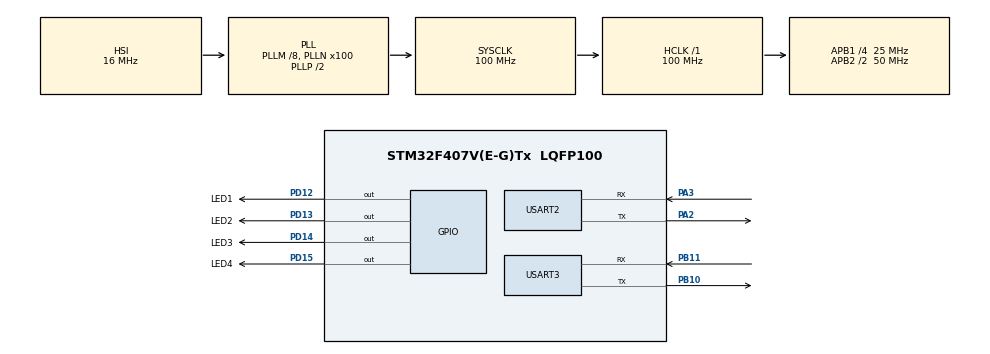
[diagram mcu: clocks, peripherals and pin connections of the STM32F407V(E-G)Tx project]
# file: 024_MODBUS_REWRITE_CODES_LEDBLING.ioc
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Mcu.Family=STM32F4
Mcu.Name=STM32F407V(E-G)Tx
Mcu.Package=LQFP100
NVIC.PriorityGroup=NVIC_PRIORITYGROUP_4
NVIC.TIM1_UP_TIM10_IRQn=true\:0\:0\:false\:false\:true\:true\:true\:true
NVIC.USART2_IRQn=true\:0\:0\:false\:false\:true\:true\:true\:true
PA13.Mode=Serial_Wire
PA13.Signal=SYS_JTMS-SWDIO
PA14.Mode=Serial_Wire
PA14.Signal=SYS_JTCK-SWCLK
PA2.Mode=Asynchronous
PA2.Signal=USART2_TX
PA3.Mode=Asynchronous
PA3.Signal=USART2_RX
PB10.Mode=Asynchronous
PB10.Signal=USART3_TX
PB11.Mode=Asynchronous
PB11.Signal=USART3_RX
PC14-OSC32_IN.Mode=LSE-External-Oscillator
PC14-OSC32_IN.Signal=RCC_OSC32_IN
PC15-OSC32_OUT.Mode=LSE-External-Oscillator
PC15-OSC32_OUT.Signal=RCC_OSC32_OUT
PD12.GPIO_Label=LED1
PD12.Signal=GPIO_Output
PD13.GPIO_Label=LED2
PD13.Signal=GPIO_Output
PD14.GPIO_Label=LED3
PD14.Signal=GPIO_Output
PD15.GPIO_Label=LED4
PD15.Signal=GPIO_Output
PH0-OSC_IN.Mode=HSE-External-Oscillator
PH0-OSC_IN.Signal=RCC_OSC_IN
PH1-OSC_OUT.Mode=HSE-External-Oscillator
PH1-OSC_OUT.Signal=RCC_OSC_OUT
ProjectManager.HeapSize=0x200
ProjectManager.StackSize=0x400
ProjectManager.TargetToolchain=STM32CubeIDE
RCC.48MHZClocksFreq_Value=50000000
RCC.AHBFreq_Value=100000000
RCC.APB1CLKDivider=RCC_HCLK_DIV4
RCC.APB1Freq_Value=25000000
RCC.APB1TimFreq_Value=50000000
RCC.APB2CLKDivider=RCC_HCLK_DIV2
RCC.APB2Freq_Value=50000000
RCC.APB2TimFreq_Value=100000000
RCC.CortexFreq_Value=100000000
RCC.HCLKFreq_Value=100000000
RCC.HSE_VALUE=25000000
RCC.HSI_VALUE=16000000
RCC.PLLM=8
RCC.PLLN=100
RCC.SYSCLKFreq_VALUE=100000000
RCC.SYSCLKSource=RCC_SYSCLKSOURCE_PLLCLK
RCC.VCOOutputFreq_Value=200000000
TIM10.Period=10000
TIM10.Prescaler=10000
USART2.VirtualMode=VM_ASYNC
USART3.VirtualMode=VM_ASYNC
VP_TIM10_VS_ClockSourceINT.Mode=Enable_Timer
VP_TIM1_VS_ClockSourceINT.Mode=Internal
board=custom

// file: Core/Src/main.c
/* USER CODE BEGIN Header */
/**
  ******************************************************************************
  * @file           : main.c
  * @brief          : Main program body
  ******************************************************************************
  * @attention
  *
  * Copyright (c) 2024 STMicroelectronics.
  * All rights reserved.
  *
  * This software is licensed under terms that can be found in the LICENSE file
  * in the root directory of this software component.
  * If no LICENSE file comes with this software, it is provided AS-IS.
  *
  ******************************************************************************
  */
/* USER CODE END Header */
#include "main.h"

/* USER CODE BEGIN Includes */
#include "string.h"
/* USER CODE END Includes */

TIM_HandleTypeDef htim1;
TIM_HandleTypeDef htim10;

UART_HandleTypeDef huart2;
UART_HandleTypeDef huart3;
uint8_t txData[] = "UART Test";  // Gönderilecek veri
uint8_t rxData[sizeof(txData)];  // Alınan veriyi saklamak için
uint8_t message[] = "UART Test Passed\r\n";  // Başarılı mesajı

void SystemClock_Config(void);
static void MX_GPIO_Init(void);
static void MX_TIM1_Init(void);
static void MX_TIM10_Init(void);
static void MX_USART2_UART_Init(void);
static void MX_USART3_UART_Init(void);

int main(void)
{

  /* MCU Configuration--------------------------------------------------------*/

  /* Reset of all peripherals, Initializes the Flash interface and the Systick. */
  HAL_Init();

  /* Configure the system clock */
  SystemClock_Config();

  /* Initialize all configured peripherals */
  MX_GPIO_Init();
  MX_TIM1_Init();
  MX_TIM10_Init();
  MX_USART2_UART_Init();
  MX_USART3_UART_Init();
  /* USER CODE BEGIN 2 */
char message[32]="Hello World";
  /* USER CODE END 2 */

  /* Infinite loop */
  /* USER CODE BEGIN WHILE */
  while (1) {
      // Gönderilen veriyi UART üzerinden gönder
	  HAL_UART_Transmit(&huart2, (uint8_t*)message, strlen(message), 100);
	 	  HAL_Delay(500);
    }

  /* USER CODE END 3 */
}

void SystemClock_Config(void)
{
  RCC_OscInitTypeDef RCC_OscInitStruct = {0};
  RCC_ClkInitTypeDef RCC_ClkInitStruct = {0};

  /** Configure the main internal regulator output voltage
  */
  __HAL_RCC_PWR_CLK_ENABLE();
  __HAL_PWR_VOLTAGESCALING_CONFIG(PWR_REGULATOR_VOLTAGE_SCALE1);

  /** Initializes the RCC Oscillators according to the specified parameters
  * in the RCC_OscInitTypeDef structure.
  */
  RCC_OscInitStruct.OscillatorType = RCC_OSCILLATORTYPE_HSI;
  RCC_OscInitStruct.HSIState = RCC_HSI_ON;
  RCC_OscInitStruct.HSICalibrationValue = RCC_HSICALIBRATION_DEFAULT;
  RCC_OscInitStruct.PLL.PLLState = RCC_PLL_ON;
  RCC_OscInitStruct.PLL.PLLSource = RCC_PLLSOURCE_HSI;
  RCC_OscInitStruct.PLL.PLLM = 8;
  RCC_OscInitStruct.PLL.PLLN = 100;
  RCC_OscInitStruct.PLL.PLLP = RCC_PLLP_DIV2;
  RCC_OscInitStruct.PLL.PLLQ = 4;
  if (HAL_RCC_OscConfig(&RCC_OscInitStruct) != HAL_OK)
  {
    Error_Handler();
  }

  /** Initializes the CPU, AHB and APB buses clocks
  */
  RCC_ClkInitStruct.ClockType = RCC_CLOCKTYPE_HCLK|RCC_CLOCKTYPE_SYSCLK
                              |RCC_CLOCKTYPE_PCLK1|RCC_CLOCKTYPE_PCLK2;
  RCC_ClkInitStruct.SYSCLKSource = RCC_SYSCLKSOURCE_PLLCLK;
  RCC_ClkInitStruct.AHBCLKDivider = RCC_SYSCLK_DIV1;
  RCC_ClkInitStruct.APB1CLKDivider = RCC_HCLK_DIV4;
  RCC_ClkInitStruct.APB2CLKDivider = RCC_HCLK_DIV2;

  if (HAL_RCC_ClockConfig(&RCC_ClkInitStruct, FLASH_LATENCY_3) != HAL_OK)
  {
    Error_Handler();
  }
}

static void MX_TIM1_Init(void)
{

  TIM_ClockConfigTypeDef sClockSourceConfig = {0};
  TIM_MasterConfigTypeDef sMasterConfig = {0};

  htim1.Instance = TIM1;
  htim1.Init.Prescaler = 0;
  htim1.Init.CounterMode = TIM_COUNTERMODE_UP;
  htim1.Init.Period = 65535;
  htim1.Init.ClockDivision = TIM_CLOCKDIVISION_DIV1;
  htim1.Init.RepetitionCounter = 0;
  htim1.Init.AutoReloadPreload = TIM_AUTORELOAD_PRELOAD_DISABLE;
  if (HAL_TIM_Base_Init(&htim1) != HAL_OK)
  {
    Error_Handler();
  }
  sClockSourceConfig.ClockSource = TIM_CLOCKSOURCE_INTERNAL;
  if (HAL_TIM_ConfigClockSource(&htim1, &sClockSourceConfig) != HAL_OK)
  {
    Error_Handler();
  }
  sMasterConfig.MasterOutputTrigger = TIM_TRGO_RESET;
  sMasterConfig.MasterSlaveMode = TIM_MASTERSLAVEMODE_DISABLE;
  if (HAL_TIMEx_MasterConfigSynchronization(&htim1, &sMasterConfig) != HAL_OK)
  {
    Error_Handler();
  }

}

static void MX_TIM10_Init(void)
{

  htim10.Instance = TIM10;
  htim10.Init.Prescaler = 10000;
  htim10.Init.CounterMode = TIM_COUNTERMODE_UP;
  htim10.Init.Period = 10000;
  htim10.Init.ClockDivision = TIM_CLOCKDIVISION_DIV1;
  htim10.Init.AutoReloadPreload = TIM_AUTORELOAD_PRELOAD_DISABLE;
  if (HAL_TIM_Base_Init(&htim10) != HAL_OK)
  {
    Error_Handler();
  }

}

static void MX_USART2_UART_Init(void)
{

  huart2.Instance = USART2;
  huart2.Init.BaudRate = 115200;
  huart2.Init.WordLength = UART_WORDLENGTH_8B;
  huart2.Init.StopBits = UART_STOPBITS_1;
  huart2.Init.Parity = UART_PARITY_NONE;
  huart2.Init.Mode = UART_MODE_TX_RX;
  huart2.Init.HwFlowCtl = UART_HWCONTROL_NONE;
  huart2.Init.OverSampling = UART_OVERSAMPLING_16;
  if (HAL_UART_Init(&huart2) != HAL_OK)
  {
    Error_Handler();
  }

}

static void MX_USART3_UART_Init(void)
{

  huart3.Instance = USART3;
  huart3.Init.BaudRate = 115200;
  huart3.Init.WordLength = UART_WORDLENGTH_8B;
  huart3.Init.StopBits = UART_STOPBITS_1;
  huart3.Init.Parity = UART_PARITY_NONE;
  huart3.Init.Mode = UART_MODE_TX_RX;
  huart3.Init.HwFlowCtl = UART_HWCONTROL_NONE;
  huart3.Init.OverSampling = UART_OVERSAMPLING_16;
  if (HAL_UART_Init(&huart3) != HAL_OK)
  {
    Error_Handler();
  }

}

static void MX_GPIO_Init(void)
{
  GPIO_InitTypeDef GPIO_InitStruct = {0};

  /* GPIO Ports Clock Enable */
  __HAL_RCC_GPIOC_CLK_ENABLE();
  __HAL_RCC_GPIOH_CLK_ENABLE();
  __HAL_RCC_GPIOA_CLK_ENABLE();
  __HAL_RCC_GPIOB_CLK_ENABLE();
  __HAL_RCC_GPIOD_CLK_ENABLE();

  /*Configure GPIO pin Output Level */
  HAL_GPIO_WritePin(GPIOD, LED1_Pin|LED2_Pin|LED3_Pin|LED4_Pin, GPIO_PIN_RESET);

  /*Configure GPIO pins : LED1_Pin LED2_Pin LED3_Pin LED4_Pin */
  GPIO_InitStruct.Pin = LED1_Pin|LED2_Pin|LED3_Pin|LED4_Pin;
  GPIO_InitStruct.Mode = GPIO_MODE_OUTPUT_PP;
  GPIO_InitStruct.Pull = GPIO_NOPULL;
  GPIO_InitStruct.Speed = GPIO_SPEED_FREQ_LOW;
  HAL_GPIO_Init(GPIOD, &GPIO_InitStruct);

}

void Error_Handler(void)
{
  __disable_irq();
  while (1)
  {
  }
}
